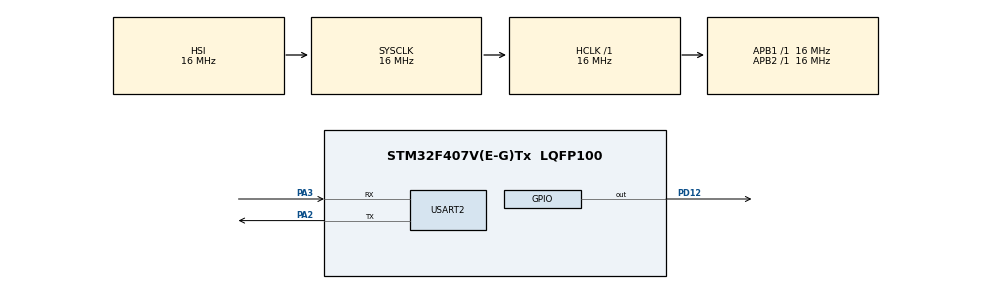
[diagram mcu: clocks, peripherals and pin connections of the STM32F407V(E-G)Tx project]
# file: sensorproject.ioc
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ADC1.Channel-1\#ChannelRegularConversion=ADC_CHANNEL_TEMPSENSOR
ADC1.ClockPrescaler=ADC_CLOCK_SYNC_PCLK_DIV4
ADC1.ContinuousConvMode=ENABLE
ADC1.DMAContinuousRequests=DISABLE
ADC1.ExternalTrigConv=ADC_SOFTWARE_START
ADC1.NbrOfConversionFlag=1
ADC1.Rank-1\#ChannelRegularConversion=1
ADC1.SamplingTime-1\#ChannelRegularConversion=ADC_SAMPLETIME_56CYCLES
ADC1.master=1
Mcu.Family=STM32F4
Mcu.Name=STM32F407V(E-G)Tx
Mcu.Package=LQFP100
NVIC.PriorityGroup=NVIC_PRIORITYGROUP_4
PA2.Mode=Asynchronous
PA2.Signal=USART2_TX
PA3.Mode=Asynchronous
PA3.Signal=USART2_RX
PD12.Signal=GPIO_Output
ProjectManager.HeapSize=0x200
ProjectManager.StackSize=0x400
ProjectManager.TargetToolchain=TrueSTUDIO
RCC.AHBFreq_Value=16000000
RCC.APB1Freq_Value=16000000
RCC.APB2Freq_Value=16000000
RCC.CortexFreq_Value=16000000
RCC.HSE_VALUE=25000000
RCC.HSI_VALUE=16000000
RCC.LSE_VALUE=32768
RCC.SYSCLKFreq_VALUE=16000000
RCC.VCOOutputFreq_Value=192000000
TIM2.Period=49
TIM2.Prescaler=420
USART2.VirtualMode=VM_ASYNC
VP_ADC1_TempSens_Input.Mode=IN-TempSens
VP_TIM2_VS_ClockSourceITR.Mode=TriggerSource_ITR0
VP_TIM2_VS_ControllerModeTrigger.Mode=Trigger Mode
board=custom

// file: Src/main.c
/* USER CODE BEGIN Header */
/**
  ******************************************************************************
  * @file           : main.c
  * @brief          : Main program body
  ******************************************************************************
  * @attention
  *
  * <h2><center>&copy; Copyright (c) 2019 STMicroelectronics.
  * All rights reserved.</center></h2>
  *
  * This software component is licensed by ST under BSD 3-Clause license,
  * the "License"; You may not use this file except in compliance with the
  * License. You may obtain a copy of the License at:
  *                        opensource.org/licenses/BSD-3-Clause
  *
  ******************************************************************************
  */
/* USER CODE END Header */

#include "main.h"

ADC_HandleTypeDef hadc1;

TIM_HandleTypeDef htim2;

UART_HandleTypeDef huart2;

/* USER CODE BEGIN PV */
uint16_t AD_value;
uint16_t value;
uint16_t TemperatureC;
volatile uint32_t pData;
uint16_t ADCReadings[3];
/* USER CODE END PV */

void SystemClock_Config(void);
static void MX_GPIO_Init(void);
static void MX_ADC1_Init(void);
static void MX_USART2_UART_Init(void);
static void MX_TIM2_Init(void);

int main(void)
{

  /* MCU Configuration--------------------------------------------------------*/

  /* Reset of all peripherals, Initializes the Flash interface and the Systick. */
  HAL_Init();

  /* Configure the system clock */
  SystemClock_Config();

  /* Initialize all configured peripherals */
  MX_GPIO_Init();
  MX_ADC1_Init();
  MX_USART2_UART_Init();
  MX_TIM2_Init();
  /* USER CODE BEGIN 2 */

  HAL_ADC_Start(& hadc1);
  while(!__HAL_ADC_GET_FLAG(&hadc1, ADC_FLAG_EOC)){};

  AD_value= HAL_ADC_GetValue(& hadc1) ;

  TemperatureC=((AD_value-943)/3)+25;

  __HAL_ADC_CLEAR_FLAG(&hadc1, ADC_FLAG_EOC);

  //HAL_ADC_Start_DMA(&hadc1,(uint32_t*) ADCReadings, 3);

  /* USER CODE END 2 */

  /* Infinite loop */
  while (1)
  {

    /* USER CODE BEGIN 3 */
	  if (TemperatureC > 37 )
	   	  {
	   		  HAL_GPIO_TogglePin( GPIOD, GPIO_PIN_12);
	   		HAL_Delay(100);
	   	  }
	   	  else
	   	  {
	   		  HAL_GPIO_WritePin(GPIOD,  GPIO_PIN_12, GPIO_PIN_SET);
	   	  }

  }
  /* USER CODE END 3 */
}

void SystemClock_Config(void)
{
  RCC_OscInitTypeDef RCC_OscInitStruct = {0};
  RCC_ClkInitTypeDef RCC_ClkInitStruct = {0};

  /** Configure the main internal regulator output voltage
  */
  __HAL_RCC_PWR_CLK_ENABLE();
  __HAL_PWR_VOLTAGESCALING_CONFIG(PWR_REGULATOR_VOLTAGE_SCALE1);
  /** Initializes the CPU, AHB and APB busses clocks
  */
  RCC_OscInitStruct.OscillatorType = RCC_OSCILLATORTYPE_HSI;
  RCC_OscInitStruct.HSIState = RCC_HSI_ON;
  RCC_OscInitStruct.HSICalibrationValue = RCC_HSICALIBRATION_DEFAULT;
  RCC_OscInitStruct.PLL.PLLState = RCC_PLL_NONE;
  if (HAL_RCC_OscConfig(&RCC_OscInitStruct) != HAL_OK)
  {
    Error_Handler();
  }
  /** Initializes the CPU, AHB and APB busses clocks
  */
  RCC_ClkInitStruct.ClockType = RCC_CLOCKTYPE_HCLK|RCC_CLOCKTYPE_SYSCLK
                              |RCC_CLOCKTYPE_PCLK1|RCC_CLOCKTYPE_PCLK2;
  RCC_ClkInitStruct.SYSCLKSource = RCC_SYSCLKSOURCE_HSI;
  RCC_ClkInitStruct.AHBCLKDivider = RCC_SYSCLK_DIV1;
  RCC_ClkInitStruct.APB1CLKDivider = RCC_HCLK_DIV1;
  RCC_ClkInitStruct.APB2CLKDivider = RCC_HCLK_DIV1;

  if (HAL_RCC_ClockConfig(&RCC_ClkInitStruct, FLASH_LATENCY_0) != HAL_OK)
  {
    Error_Handler();
  }
}

static void MX_ADC1_Init(void)
{

  ADC_ChannelConfTypeDef sConfig = {0};

  /** Configure the global features of the ADC (Clock, Resolution, Data Alignment and number of conversion)
  */
  hadc1.Instance = ADC1;
  hadc1.Init.ClockPrescaler = ADC_CLOCK_SYNC_PCLK_DIV4;
  hadc1.Init.Resolution = ADC_RESOLUTION_12B;
  hadc1.Init.ScanConvMode = DISABLE;
  hadc1.Init.ContinuousConvMode = ENABLE;
  hadc1.Init.DiscontinuousConvMode = DISABLE;
  hadc1.Init.ExternalTrigConvEdge = ADC_EXTERNALTRIGCONVEDGE_NONE;
  hadc1.Init.ExternalTrigConv = ADC_SOFTWARE_START;
  hadc1.Init.DataAlign = ADC_DATAALIGN_RIGHT;
  hadc1.Init.NbrOfConversion = 1;
  hadc1.Init.DMAContinuousRequests = DISABLE;
  hadc1.Init.EOCSelection = ADC_EOC_SINGLE_CONV;
  if (HAL_ADC_Init(&hadc1) != HAL_OK)
  {
    Error_Handler();
  }
  /** Configure for the selected ADC regular channel its corresponding rank in the sequencer and its sample time.
  */
  sConfig.Channel = ADC_CHANNEL_TEMPSENSOR;
  sConfig.Rank = 1;
  sConfig.SamplingTime = ADC_SAMPLETIME_56CYCLES;
  if (HAL_ADC_ConfigChannel(&hadc1, &sConfig) != HAL_OK)
  {
    Error_Handler();
  }

}

static void MX_TIM2_Init(void)
{

  TIM_SlaveConfigTypeDef sSlaveConfig = {0};
  TIM_MasterConfigTypeDef sMasterConfig = {0};

  htim2.Instance = TIM2;
  htim2.Init.Prescaler = 420;
  htim2.Init.CounterMode = TIM_COUNTERMODE_UP;
  htim2.Init.Period = 49;
  htim2.Init.ClockDivision = TIM_CLOCKDIVISION_DIV1;
  htim2.Init.AutoReloadPreload = TIM_AUTORELOAD_PRELOAD_DISABLE;
  if (HAL_TIM_Base_Init(&htim2) != HAL_OK)
  {
    Error_Handler();
  }
  sSlaveConfig.SlaveMode = TIM_SLAVEMODE_TRIGGER;
  sSlaveConfig.InputTrigger = TIM_TS_ITR0;
  if (HAL_TIM_SlaveConfigSynchro(&htim2, &sSlaveConfig) != HAL_OK)
  {
    Error_Handler();
  }
  sMasterConfig.MasterOutputTrigger = TIM_TRGO_RESET;
  sMasterConfig.MasterSlaveMode = TIM_MASTERSLAVEMODE_DISABLE;
  if (HAL_TIMEx_MasterConfigSynchronization(&htim2, &sMasterConfig) != HAL_OK)
  {
    Error_Handler();
  }

}

static void MX_USART2_UART_Init(void)
{

  huart2.Instance = USART2;
  huart2.Init.BaudRate = 115200;
  huart2.Init.WordLength = UART_WORDLENGTH_8B;
  huart2.Init.StopBits = UART_STOPBITS_1;
  huart2.Init.Parity = UART_PARITY_NONE;
  huart2.Init.Mode = UART_MODE_TX_RX;
  huart2.Init.HwFlowCtl = UART_HWCONTROL_NONE;
  huart2.Init.OverSampling = UART_OVERSAMPLING_16;
  if (HAL_UART_Init(&huart2) != HAL_OK)
  {
    Error_Handler();
  }

}

static void MX_GPIO_Init(void)
{
  GPIO_InitTypeDef GPIO_InitStruct = {0};

  /* GPIO Ports Clock Enable */
  __HAL_RCC_GPIOA_CLK_ENABLE();
  __HAL_RCC_GPIOD_CLK_ENABLE();

  /*Configure GPIO pin Output Level */
  HAL_GPIO_WritePin(GPIOD, GPIO_PIN_12, GPIO_PIN_RESET);

  /*Configure GPIO pin : PD12 */
  GPIO_InitStruct.Pin = GPIO_PIN_12;
  GPIO_InitStruct.Mode = GPIO_MODE_OUTPUT_PP;
  GPIO_InitStruct.Pull = GPIO_NOPULL;
  GPIO_InitStruct.Speed = GPIO_SPEED_FREQ_LOW;
  HAL_GPIO_Init(GPIOD, &GPIO_InitStruct);

}

void Error_Handler(void)
{
}

/************************ (C) COPYRIGHT STMicroelectronics *****END OF FILE****/
